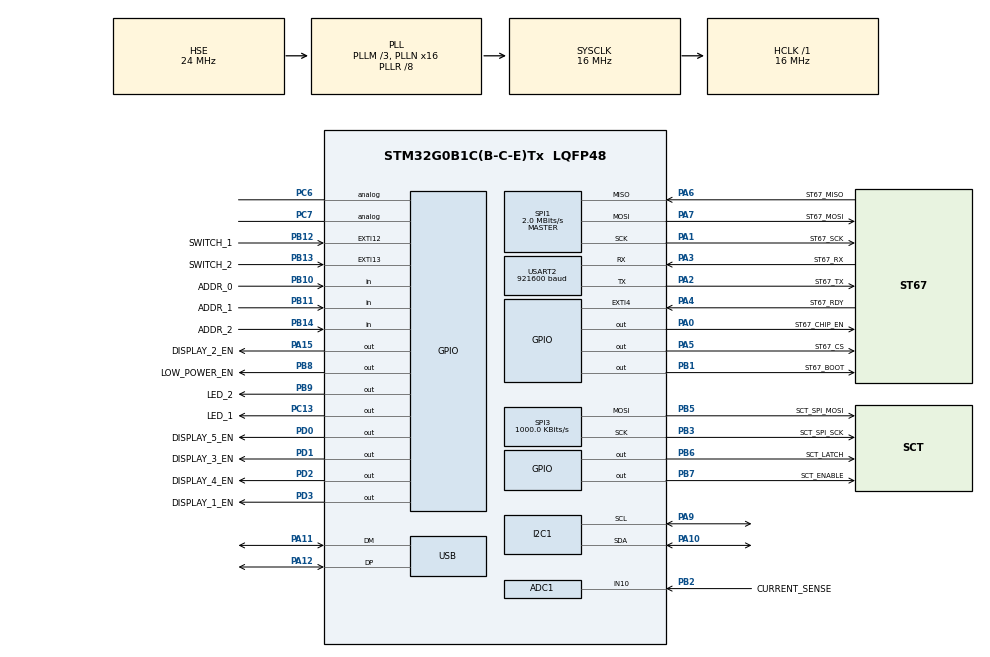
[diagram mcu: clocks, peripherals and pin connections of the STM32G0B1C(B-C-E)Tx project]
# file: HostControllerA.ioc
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ADC1.Channel-0\#ChannelRegularConversion=ADC_CHANNEL_10
ADC1.Channel-1\#ChannelRegularConversion=ADC_CHANNEL_TEMPSENSOR
ADC1.Channel-2\#ChannelRegularConversion=ADC_CHANNEL_VREFINT
ADC1.NbrOfConversion=3
ADC1.NbrOfConversionFlag=1
ADC1.OversamplingMode=ENABLE
ADC1.Rank-0\#ChannelRegularConversion=1
ADC1.Rank-1\#ChannelRegularConversion=2
ADC1.Rank-2\#ChannelRegularConversion=3
ADC1.Ratio=ADC_OVERSAMPLING_RATIO_16
ADC1.RightBitShift=ADC_RIGHTBITSHIFT_4
ADC1.SamplingTime-0\#ChannelRegularConversion=ADC_SAMPLINGTIME_COMMON_1
ADC1.SamplingTime-1\#ChannelRegularConversion=ADC_SAMPLINGTIME_COMMON_1
ADC1.SamplingTime-2\#ChannelRegularConversion=ADC_SAMPLINGTIME_COMMON_1
ADC1.SamplingTimeCommon1=ADC_SAMPLETIME_160CYCLES_5
ADC1.SamplingTimeCommon2=ADC_SAMPLETIME_160CYCLES_5
ADC1.SelectedChannel=ADC_CHANNEL_TEMPSENSOR|ADC_CHANNEL_VREFINT|ADC_CHANNEL_10
ADC1.TriggerFrequencyMode=ADC_TRIGGER_FREQ_LOW
ADC1.master=1
Dma.ADC1.2.Direction=DMA_PERIPH_TO_MEMORY
Dma.ADC1.2.EventEnable=DISABLE
Dma.ADC1.2.Instance=DMA1_Channel3
Dma.ADC1.2.MemDataAlignment=DMA_MDATAALIGN_HALFWORD
Dma.ADC1.2.MemInc=DMA_MINC_ENABLE
Dma.ADC1.2.Mode=DMA_NORMAL
Dma.ADC1.2.PeriphDataAlignment=DMA_PDATAALIGN_HALFWORD
Dma.ADC1.2.PeriphInc=DMA_PINC_DISABLE
Dma.ADC1.2.Polarity=HAL_DMAMUX_REQ_GEN_RISING
Dma.ADC1.2.Priority=DMA_PRIORITY_LOW
Dma.ADC1.2.RequestNumber=1
Dma.ADC1.2.SignalID=NONE
Dma.ADC1.2.SyncEnable=DISABLE
Dma.ADC1.2.SyncPolarity=HAL_DMAMUX_SYNC_NO_EVENT
Dma.ADC1.2.SyncRequestNumber=1
Dma.ADC1.2.SyncSignalID=NONE
Dma.Request0=SPI1_RX
Dma.Request1=SPI1_TX
Dma.Request2=ADC1
Dma.Request3=SPI3_TX
Dma.SPI1_RX.0.Direction=DMA_PERIPH_TO_MEMORY
Dma.SPI1_RX.0.EventEnable=DISABLE
Dma.SPI1_RX.0.Instance=DMA1_Channel1
Dma.SPI1_RX.0.MemDataAlignment=DMA_MDATAALIGN_BYTE
Dma.SPI1_RX.0.MemInc=DMA_MINC_ENABLE
Dma.SPI1_RX.0.Mode=DMA_NORMAL
Dma.SPI1_RX.0.PeriphDataAlignment=DMA_PDATAALIGN_BYTE
Dma.SPI1_RX.0.PeriphInc=DMA_PINC_DISABLE
Dma.SPI1_RX.0.Polarity=HAL_DMAMUX_REQ_GEN_RISING
Dma.SPI1_RX.0.Priority=DMA_PRIORITY_HIGH
Dma.SPI1_RX.0.RequestNumber=1
Dma.SPI1_RX.0.SignalID=NONE
Dma.SPI1_RX.0.SyncEnable=DISABLE
Dma.SPI1_RX.0.SyncPolarity=HAL_DMAMUX_SYNC_NO_EVENT
Dma.SPI1_RX.0.SyncRequestNumber=1
Dma.SPI1_RX.0.SyncSignalID=NONE
Dma.SPI1_TX.1.Direction=DMA_MEMORY_TO_PERIPH
Dma.SPI1_TX.1.EventEnable=DISABLE
Dma.SPI1_TX.1.Instance=DMA1_Channel2
Dma.SPI1_TX.1.MemDataAlignment=DMA_MDATAALIGN_BYTE
Dma.SPI1_TX.1.MemInc=DMA_MINC_ENABLE
Dma.SPI1_TX.1.Mode=DMA_NORMAL
Dma.SPI1_TX.1.PeriphDataAlignment=DMA_PDATAALIGN_BYTE
Dma.SPI1_TX.1.PeriphInc=DMA_PINC_DISABLE
Dma.SPI1_TX.1.Polarity=HAL_DMAMUX_REQ_GEN_RISING
Dma.SPI1_TX.1.Priority=DMA_PRIORITY_HIGH
Dma.SPI1_TX.1.RequestNumber=1
Dma.SPI1_TX.1.SignalID=NONE
Dma.SPI1_TX.1.SyncEnable=DISABLE
Dma.SPI1_TX.1.SyncPolarity=HAL_DMAMUX_SYNC_NO_EVENT
Dma.SPI1_TX.1.SyncRequestNumber=1
Dma.SPI1_TX.1.SyncSignalID=NONE
Dma.SPI3_TX.3.Direction=DMA_MEMORY_TO_PERIPH
Dma.SPI3_TX.3.EventEnable=DISABLE
Dma.SPI3_TX.3.Instance=DMA1_Channel4
Dma.SPI3_TX.3.MemDataAlignment=DMA_MDATAALIGN_BYTE
Dma.SPI3_TX.3.MemInc=DMA_MINC_ENABLE
Dma.SPI3_TX.3.Mode=DMA_NORMAL
Dma.SPI3_TX.3.PeriphDataAlignment=DMA_PDATAALIGN_BYTE
Dma.SPI3_TX.3.PeriphInc=DMA_PINC_DISABLE
Dma.SPI3_TX.3.Polarity=HAL_DMAMUX_REQ_GEN_RISING
Dma.SPI3_TX.3.Priority=DMA_PRIORITY_HIGH
Dma.SPI3_TX.3.RequestNumber=1
Dma.SPI3_TX.3.SignalID=NONE
Dma.SPI3_TX.3.SyncEnable=DISABLE
Dma.SPI3_TX.3.SyncPolarity=HAL_DMAMUX_SYNC_NO_EVENT
Dma.SPI3_TX.3.SyncRequestNumber=1
Dma.SPI3_TX.3.SyncSignalID=NONE
FREERTOS.Tasks01=defaultTask,24,128,StartDefaultTask,Default,NULL,Dynamic,NULL,NULL
FREERTOS.configTOTAL_HEAP_SIZE=32000
FREERTOS.configUSE_NEWLIB_REENTRANT=1
I2C1.OwnAddress=8
I2C1.Speed=100
I2C1.Timing=0x00503D58
Mcu.Family=STM32G0
Mcu.Name=STM32G0B1C(B-C-E)Tx
Mcu.Package=LQFP48
NVIC.ADC1_COMP_IRQn=true\:3\:0\:false\:false\:true\:true\:true\:true\:true
NVIC.DMA1_Ch4_7_DMA2_Ch1_5_DMAMUX1_OVR_IRQn=true\:3\:0\:false\:false\:true\:true\:false\:true\:true
NVIC.DMA1_Channel1_IRQn=true\:3\:0\:false\:false\:true\:true\:false\:true\:true
NVIC.DMA1_Channel2_3_IRQn=true\:3\:0\:false\:false\:true\:true\:false\:true\:true
NVIC.EXTI4_15_IRQn=true\:3\:0\:false\:false\:true\:true\:true\:true\:true
NVIC.TIM1_BRK_UP_TRG_COM_IRQn=true\:3\:0\:false\:false\:true\:false\:false\:true\:true
NVIC.TIM2_IRQn=true\:3\:0\:false\:false\:true\:true\:true\:true\:true
NVIC.TimeBase=TIM1_BRK_UP_TRG_COM_IRQn
NVIC.TimeBaseIP=TIM1
NVIC.USB_UCPD1_2_IRQn=true\:1\:0\:false\:false\:true\:true\:true\:true\:true
PA0.GPIO_Label=ST67_CHIP_EN
PA0.GPIO_Speed=GPIO_SPEED_FREQ_HIGH
PA0.Signal=GPIO_Output
PA1.GPIO_Label=ST67_SCK
PA1.GPIO_Speed=GPIO_SPEED_FREQ_VERY_HIGH
PA1.Mode=Full_Duplex_Master
PA1.Signal=SPI1_SCK
PA10.GPIO_Pu=GPIO_NOPULL
PA10.Mode=I2C
PA10.Signal=I2C1_SDA
PA11\ [PA9].Mode=Device
PA11\ [PA9].Signal=USB_DM
PA12\ [PA10].Mode=Device
PA12\ [PA10].Signal=USB_DP
PA13.Mode=Serial_Wire
PA13.Signal=SYS_SWDIO
PA14-BOOT0.Mode=Serial_Wire
PA14-BOOT0.Signal=SYS_SWCLK
PA15.GPIO_Label=DISPLAY_2_EN
PA15.PinState=GPIO_PIN_SET
PA15.Signal=GPIO_Output
PA2.GPIO_Label=ST67_TX
PA2.Mode=Asynchronous
PA2.Signal=USART2_TX
PA3.GPIO_Label=ST67_RX
PA3.Mode=Asynchronous
PA3.Signal=USART2_RX
PA4.GPIO_Label=ST67_RDY
PA4.GPIO_ModeDefaultEXTI=GPIO_MODE_IT_RISING_FALLING
PA4.GPIO_PuPd=GPIO_PULLDOWN
PA4.Signal=GPXTI4
PA5.GPIO_Label=ST67_CS
PA5.GPIO_Speed=GPIO_SPEED_FREQ_HIGH
PA5.Signal=GPIO_Output
PA6.GPIO_Label=ST67_MISO
PA6.GPIO_Speed=GPIO_SPEED_FREQ_VERY_HIGH
PA6.Mode=Full_Duplex_Master
PA6.Signal=SPI1_MISO
PA7.GPIO_Label=ST67_MOSI
PA7.GPIO_Speed=GPIO_SPEED_FREQ_VERY_HIGH
PA7.Mode=Full_Duplex_Master
PA7.Signal=SPI1_MOSI
PA9.GPIO_Pu=GPIO_NOPULL
PA9.Mode=I2C
PA9.Signal=I2C1_SCL
PB1.GPIO_Label=ST67_BOOT
PB1.Signal=GPIO_Output
PB10.GPIO_Label=ADDR_0
PB10.GPIO_PuPd=GPIO_PULLDOWN
PB10.Signal=GPIO_Input
PB11.GPIO_Label=ADDR_1
PB11.GPIO_PuPd=GPIO_PULLDOWN
PB11.Signal=GPIO_Input
PB12.GPIO_Label=SWITCH_1
PB12.GPIO_ModeDefaultEXTI=GPIO_MODE_IT_FALLING
PB12.GPIO_PuPd=GPIO_PULLUP
PB12.Signal=GPXTI12
PB13.GPIO_Label=SWITCH_2
PB13.GPIO_ModeDefaultEXTI=GPIO_MODE_IT_FALLING
PB13.GPIO_PuPd=GPIO_PULLUP
PB13.Signal=GPXTI13
PB14.GPIO_Label=ADDR_2
PB14.GPIO_PuPd=GPIO_PULLDOWN
PB14.Signal=GPIO_Input
PB2.GPIO_Label=CURRENT_SENSE
PB2.Mode=IN10
PB2.Signal=ADC1_IN10
PB3.GPIO_Label=SCT_SPI_SCK
PB3.Mode=TX_Only_Simplex_Unidirect_Master
PB3.Signal=SPI3_SCK
PB5.GPIO_Label=SCT_SPI_MOSI
PB5.Mode=TX_Only_Simplex_Unidirect_Master
PB5.Signal=SPI3_MOSI
PB6.GPIO_Label=SCT_LATCH
PB6.Signal=GPIO_Output
PB7.GPIO_Label=SCT_ENABLE
PB7.Signal=GPIO_Output
PB8.GPIO_Label=LOW_POWER_EN
PB8.Signal=GPIO_Output
PB9.GPIO_Label=LED_2
PB9.Signal=GPIO_Output
PC13.GPIO_Label=LED_1
PC13.Signal=GPIO_Output
PC6.Signal=GPIO_Analog
PC7.Signal=GPIO_Analog
PD0.GPIO_Label=DISPLAY_5_EN
PD0.PinState=GPIO_PIN_SET
PD0.Signal=GPIO_Output
PD1.GPIO_Label=DISPLAY_3_EN
PD1.PinState=GPIO_PIN_SET
PD1.Signal=GPIO_Output
PD2.GPIO_Label=DISPLAY_4_EN
PD2.PinState=GPIO_PIN_SET
PD2.Signal=GPIO_Output
PD3.GPIO_Label=DISPLAY_1_EN
PD3.PinState=GPIO_PIN_SET
PD3.Signal=GPIO_Output
PF0-OSC_IN\ (PF0).Mode=HSE-External-Oscillator
PF0-OSC_IN\ (PF0).Signal=RCC_OSC_IN
PF1-OSC_OUT\ (PF1).Mode=HSE-External-Oscillator
PF1-OSC_OUT\ (PF1).Signal=RCC_OSC_OUT
ProjectManager.HeapSize=0x200
ProjectManager.StackSize=0x400
ProjectManager.TargetToolchain=CMake
RCC.AHBFreq_Value=16000000
RCC.CortexFreq_Value=16000000
RCC.EXTERNAL_CLOCK_VALUE=48000
RCC.HCLKFreq_Value=16000000
RCC.HSE_VALUE=24000000
RCC.HSI48_VALUE=48000000
RCC.HSI_VALUE=16000000
RCC.LSE_VALUE=32768
RCC.PLLM=RCC_PLLM_DIV3
RCC.PLLN=16
RCC.PLLR=RCC_PLLR_DIV8
RCC.PLLSourceVirtual=RCC_PLLSOURCE_HSE
RCC.RTCClockSelection=RCC_RTCCLKSOURCE_HSE_DIV32
RCC.SYSCLKFreq_VALUE=16000000
RCC.SYSCLKSource=RCC_SYSCLKSOURCE_PLLCLK
RCC.USBFreq_Value=48000000
RCC.VCOOutputFreq_Value=128000000
RTC.AsynchPrediv=124
RTC.Format=RTC_FORMAT_BIN
RTC.Month=RTC_MONTH_SEPTEMBER
RTC.SynchPrediv=5999
SPI1.BaudRatePrescaler=SPI_BAUDRATEPRESCALER_8
SPI1.CalculateBaudRate=2.0 MBits/s
SPI1.DataSize=SPI_DATASIZE_8BIT
SPI1.Direction=SPI_DIRECTION_2LINES
SPI1.Mode=SPI_MODE_MASTER
SPI1.VirtualType=VM_MASTER
SPI3.BaudRatePrescaler=SPI_BAUDRATEPRESCALER_16
SPI3.CalculateBaudRate=1000.0 KBits/s
SPI3.DataSize=SPI_DATASIZE_8BIT
SPI3.Direction=SPI_DIRECTION_2LINES
SPI3.Mode=SPI_MODE_MASTER
SPI3.VirtualType=VM_MASTER
STMicroelectronics.X-CUBE-ST67W61.1.3.0.BSP.number=1
STMicroelectronics.X-CUBE-ST67W61.1.3.0.ST67W6XIiNetworkIiDriverCcNetworkJjATDriver=true
STMicroelectronics.X-CUBE-ST67W61.1.3.0.ST67W6XIiNetworkIiDriverCcNetworkJjST67OoArchitecture=T01
STMicroelectronics.X-CUBE-ST67W61.1.3.0.ST67W6XIiNetworkIiDriverCcNetworkJjServiceAPI=true
STMicroelectronics.X-CUBE-ST67W61.1.3.00.BSP.STBoard=false
STMicroelectronics.X-CUBE-ST67W61.1.3.00.BSP.api=Unknown
STMicroelectronics.X-CUBE-ST67W61.1.3.00.BSP.instance=SPI1
STMicroelectronics.X-CUBE-ST67W61.1.3.00.BSP.ip=SPI
STMicroelectronics.X-CUBE-ST67W61.1.3.00.BSP.mode=Full-Duplex Master
STMicroelectronics.X-CUBE-ST67W61.1.3.00.BSP.name=NCP_SPI
STMicroelectronics.X-CUBE-ST67W61.1.3.00.BSP.solution=SPI1
TIM2.Period=3999
TIM2.Prescaler=15
USART2.BaudRate=921600
USART2.VirtualMode-Asynchronous=VM_ASYNC
USB_DEVICE.CLASS_NAME_FS=CDC
USB_DEVICE.VirtualMode=Cdc
USB_DEVICE.VirtualModeFS=Cdc_FS
VP_ADC1_TempSens_Input.Mode=IN-TempSens
VP_ADC1_Vref_Input.Mode=IN-Vrefint
VP_FREERTOS_VS_CMSIS_V2.Mode=CMSIS_V2
VP_RCC_USB.Mode=CRS SYNC Source USB
VP_RTC_VS_RTC_Activate.Mode=RTC_Enabled
VP_RTC_VS_RTC_Calendar.Mode=RTC_Calendar
VP_STMicroelectronics.X-CUBE-ST67W61_VS_NetworkJjST67W6XIiNetworkIiDriver_1.3.0_1.3.0.Mode=NetworkJjST67W6XIiNetworkIiDriver
VP_SYS_VS_DBSignals.Mode=DisableDeadBatterySignals
VP_SYS_VS_tim1.Mode=TIM1
VP_TIM2_VS_ClockSourceINT.Mode=Internal
VP_USB_DEVICE_VS_USB_DEVICE_CDC_FS.Mode=CDC_FS
board=custom

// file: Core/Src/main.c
/* USER CODE BEGIN Header */
/**
  ******************************************************************************
  * @file           : main.c
  * @brief          : Main program body
  ******************************************************************************
  * @attention
  *
  * Copyright (c) 2026 STMicroelectronics.
  * All rights reserved.
  *
  * This software is licensed under terms that can be found in the LICENSE file
  * in the root directory of this software component.
  * If no LICENSE file comes with this software, it is provided AS-IS.
  *
  ******************************************************************************
  */
/* USER CODE END Header */
#include "main.h"
#include "cmsis_os.h"
#include "usb_device.h"

/* USER CODE BEGIN Includes */
#include <AstroWeather.hpp>
#include "task.h"
#include "stm32g0xx_ll_crs.h"
/* USER CODE END Includes */

ADC_HandleTypeDef hadc1;
DMA_HandleTypeDef hdma_adc1;

I2C_HandleTypeDef hi2c1;

RTC_HandleTypeDef hrtc;

SPI_HandleTypeDef hspi1;
SPI_HandleTypeDef hspi3;
DMA_HandleTypeDef hdma_spi1_rx;
DMA_HandleTypeDef hdma_spi1_tx;
DMA_HandleTypeDef hdma_spi3_tx;

TIM_HandleTypeDef htim2;

UART_HandleTypeDef huart2;

/* Definitions for defaultTask */
osThreadId_t defaultTaskHandle;
const osThreadAttr_t defaultTask_attributes = {
  .name = "defaultTask",
  .priority = (osPriority_t) osPriorityNormal,
  .stack_size = 128 * 4
};

void SystemClock_Config(void);
static void MX_GPIO_Init(void);
static void MX_DMA_Init(void);
static void MX_SPI1_Init(void);
static void MX_USART2_UART_Init(void);
static void MX_SPI3_Init(void);
static void MX_I2C1_Init(void);
static void MX_TIM2_Init(void);
static void MX_ADC1_Init(void);
static void MX_RTC_Init(void);
void StartDefaultTask(void *argument);

int main(void)
{

  /* MCU Configuration--------------------------------------------------------*/

  /* Reset of all peripherals, Initializes the Flash interface and the Systick. */
  HAL_Init();

  /* Configure the system clock */
  SystemClock_Config();

  /* USER CODE BEGIN SysInit */
  /* CubeMX generates HSI48CalibrationValue = 32 whatever the GUI shows: the
     midpoint of the 6-bit TRIM on other families. The G0's TRIM is 7 bits
     with its midpoint and reset value at 64, so start the CRS there. USB is
     not running yet, so the CRS has not trimmed anything. */
  LL_CRS_DisableAutoTrimming();
  LL_CRS_SetHSI48SmoothTrimming(LL_CRS_HSI48CALIBRATION_DEFAULT);
  LL_CRS_EnableAutoTrimming();
  /* USER CODE END SysInit */

  /* Initialize all configured peripherals */
  MX_GPIO_Init();
  MX_DMA_Init();
  MX_SPI1_Init();
  MX_USART2_UART_Init();
  MX_SPI3_Init();
  MX_I2C1_Init();
  MX_TIM2_Init();
  MX_ADC1_Init();
  MX_RTC_Init();

  /* Init scheduler */
  osKernelInitialize();

  /* Create the thread(s) */
  /* creation of defaultTask */
  defaultTaskHandle = osThreadNew(StartDefaultTask, NULL, &defaultTask_attributes);

  /* USER CODE BEGIN RTOS_THREADS */
  AstroWeather_Init();
  /* USER CODE END RTOS_THREADS */

  /* Start scheduler */
  osKernelStart();

  /* We should never get here as control is now taken by the scheduler */

  /* Infinite loop */
  while (1)
  {

  }
}

void SystemClock_Config(void)
{
  RCC_OscInitTypeDef RCC_OscInitStruct = {0};
  RCC_ClkInitTypeDef RCC_ClkInitStruct = {0};
  RCC_CRSInitTypeDef pInit = {0};

  /** Configure the main internal regulator output voltage
  */
  HAL_PWREx_ControlVoltageScaling(PWR_REGULATOR_VOLTAGE_SCALE1);

  /** Initializes the RCC Oscillators according to the specified parameters
  * in the RCC_OscInitTypeDef structure.
  */
  RCC_OscInitStruct.OscillatorType = RCC_OSCILLATORTYPE_HSE|RCC_OSCILLATORTYPE_HSI48;
  RCC_OscInitStruct.HSEState = RCC_HSE_ON;
  RCC_OscInitStruct.HSI48State = RCC_HSI48_ON;
  RCC_OscInitStruct.PLL.PLLState = RCC_PLL_ON;
  RCC_OscInitStruct.PLL.PLLSource = RCC_PLLSOURCE_HSE;
  RCC_OscInitStruct.PLL.PLLM = RCC_PLLM_DIV3;
  RCC_OscInitStruct.PLL.PLLN = 16;
  RCC_OscInitStruct.PLL.PLLP = RCC_PLLP_DIV2;
  RCC_OscInitStruct.PLL.PLLQ = RCC_PLLQ_DIV2;
  RCC_OscInitStruct.PLL.PLLR = RCC_PLLR_DIV8;
  if (HAL_RCC_OscConfig(&RCC_OscInitStruct) != HAL_OK)
  {
    Error_Handler();
  }

  /** Initializes the CPU, AHB and APB buses clocks
  */
  RCC_ClkInitStruct.ClockType = RCC_CLOCKTYPE_HCLK|RCC_CLOCKTYPE_SYSCLK
                              |RCC_CLOCKTYPE_PCLK1;
  RCC_ClkInitStruct.SYSCLKSource = RCC_SYSCLKSOURCE_PLLCLK;
  RCC_ClkInitStruct.AHBCLKDivider = RCC_SYSCLK_DIV1;
  RCC_ClkInitStruct.APB1CLKDivider = RCC_HCLK_DIV1;

  if (HAL_RCC_ClockConfig(&RCC_ClkInitStruct, FLASH_LATENCY_0) != HAL_OK)
  {
    Error_Handler();
  }

  /** Enable the SYSCFG APB clock
  */
  __HAL_RCC_CRS_CLK_ENABLE();

  /** Configures CRS
  */
  pInit.Prescaler = RCC_CRS_SYNC_DIV1;
  pInit.Source = RCC_CRS_SYNC_SOURCE_USB;
  pInit.Polarity = RCC_CRS_SYNC_POLARITY_RISING;
  pInit.ReloadValue = __HAL_RCC_CRS_RELOADVALUE_CALCULATE(48000000,1000);
  pInit.ErrorLimitValue = 34;
  pInit.HSI48CalibrationValue = 32;

  HAL_RCCEx_CRSConfig(&pInit);
}

static void MX_ADC1_Init(void)
{

  ADC_ChannelConfTypeDef sConfig = {0};

  /** Configure the global features of the ADC (Clock, Resolution, Data Alignment and number of conversion)
  */
  hadc1.Instance = ADC1;
  hadc1.Init.ClockPrescaler = ADC_CLOCK_SYNC_PCLK_DIV2;
  hadc1.Init.Resolution = ADC_RESOLUTION_12B;
  hadc1.Init.DataAlign = ADC_DATAALIGN_RIGHT;
  hadc1.Init.ScanConvMode = ADC_SCAN_ENABLE;
  hadc1.Init.EOCSelection = ADC_EOC_SINGLE_CONV;
  hadc1.Init.LowPowerAutoWait = DISABLE;
  hadc1.Init.LowPowerAutoPowerOff = DISABLE;
  hadc1.Init.ContinuousConvMode = DISABLE;
  hadc1.Init.NbrOfConversion = 3;
  hadc1.Init.DiscontinuousConvMode = DISABLE;
  hadc1.Init.ExternalTrigConv = ADC_SOFTWARE_START;
  hadc1.Init.ExternalTrigConvEdge = ADC_EXTERNALTRIGCONVEDGE_NONE;
  hadc1.Init.DMAContinuousRequests = DISABLE;
  hadc1.Init.Overrun = ADC_OVR_DATA_PRESERVED;
  hadc1.Init.SamplingTimeCommon1 = ADC_SAMPLETIME_160CYCLES_5;
  hadc1.Init.SamplingTimeCommon2 = ADC_SAMPLETIME_160CYCLES_5;
  hadc1.Init.OversamplingMode = ENABLE;
  hadc1.Init.Oversampling.Ratio = ADC_OVERSAMPLING_RATIO_16;
  hadc1.Init.Oversampling.RightBitShift = ADC_RIGHTBITSHIFT_4;
  hadc1.Init.Oversampling.TriggeredMode = ADC_TRIGGEREDMODE_SINGLE_TRIGGER;
  hadc1.Init.TriggerFrequencyMode = ADC_TRIGGER_FREQ_LOW;
  if (HAL_ADC_Init(&hadc1) != HAL_OK)
  {
    Error_Handler();
  }

  /** Configure Regular Channel
  */
  sConfig.Channel = ADC_CHANNEL_10;
  sConfig.Rank = ADC_REGULAR_RANK_1;
  sConfig.SamplingTime = ADC_SAMPLINGTIME_COMMON_1;
  if (HAL_ADC_ConfigChannel(&hadc1, &sConfig) != HAL_OK)
  {
    Error_Handler();
  }

  /** Configure Regular Channel
  */
  sConfig.Channel = ADC_CHANNEL_TEMPSENSOR;
  sConfig.Rank = ADC_REGULAR_RANK_2;
  if (HAL_ADC_ConfigChannel(&hadc1, &sConfig) != HAL_OK)
  {
    Error_Handler();
  }

  /** Configure Regular Channel
  */
  sConfig.Channel = ADC_CHANNEL_VREFINT;
  sConfig.Rank = ADC_REGULAR_RANK_3;
  if (HAL_ADC_ConfigChannel(&hadc1, &sConfig) != HAL_OK)
  {
    Error_Handler();
  }

}

static void MX_I2C1_Init(void)
{

  hi2c1.Instance = I2C1;
  hi2c1.Init.Timing = 0x00503D58;
  hi2c1.Init.OwnAddress1 = 16;
  hi2c1.Init.AddressingMode = I2C_ADDRESSINGMODE_7BIT;
  hi2c1.Init.DualAddressMode = I2C_DUALADDRESS_DISABLE;
  hi2c1.Init.OwnAddress2 = 0;
  hi2c1.Init.OwnAddress2Masks = I2C_OA2_NOMASK;
  hi2c1.Init.GeneralCallMode = I2C_GENERALCALL_DISABLE;
  hi2c1.Init.NoStretchMode = I2C_NOSTRETCH_DISABLE;
  if (HAL_I2C_Init(&hi2c1) != HAL_OK)
  {
    Error_Handler();
  }

  /** Configure Analogue filter
  */
  if (HAL_I2CEx_ConfigAnalogFilter(&hi2c1, I2C_ANALOGFILTER_ENABLE) != HAL_OK)
  {
    Error_Handler();
  }

  /** Configure Digital filter
  */
  if (HAL_I2CEx_ConfigDigitalFilter(&hi2c1, 0) != HAL_OK)
  {
    Error_Handler();
  }

}

static void MX_RTC_Init(void)
{

  RTC_TimeTypeDef sTime = {0};
  RTC_DateTypeDef sDate = {0};

  /** Initialize RTC Only
  */
  hrtc.Instance = RTC;
  hrtc.Init.HourFormat = RTC_HOURFORMAT_24;
  hrtc.Init.AsynchPrediv = 124;
  hrtc.Init.SynchPrediv = 5999;
  hrtc.Init.OutPut = RTC_OUTPUT_DISABLE;
  hrtc.Init.OutPutRemap = RTC_OUTPUT_REMAP_NONE;
  hrtc.Init.OutPutPolarity = RTC_OUTPUT_POLARITY_HIGH;
  hrtc.Init.OutPutType = RTC_OUTPUT_TYPE_OPENDRAIN;
  hrtc.Init.OutPutPullUp = RTC_OUTPUT_PULLUP_NONE;
  if (HAL_RTC_Init(&hrtc) != HAL_OK)
  {
    Error_Handler();
  }

  /* USER CODE BEGIN Check_RTC_BKUP */
  /* Time set before a reset: keep it. HAL_RTC_Init() above left the calendar
   * and prescalers alone, as setting the time also sets a non-zero year. */
  if (HAL_RTCEx_BKUPRead(&hrtc, RTC_TIME_SET_BKP_REGISTER) == RTC_TIME_SET_MARKER)
  {
    return;
  }

  /* USER CODE END Check_RTC_BKUP */

  /** Initialize RTC and set the Time and Date
  */
  sTime.Hours = 0;
  sTime.Minutes = 0;
  sTime.Seconds = 0;
  sTime.SubSeconds = 0;
  sTime.DayLightSaving = RTC_DAYLIGHTSAVING_NONE;
  sTime.StoreOperation = RTC_STOREOPERATION_RESET;
  if (HAL_RTC_SetTime(&hrtc, &sTime, RTC_FORMAT_BIN) != HAL_OK)
  {
    Error_Handler();
  }
  sDate.WeekDay = RTC_WEEKDAY_MONDAY;
  sDate.Month = RTC_MONTH_SEPTEMBER;
  sDate.Date = 1;
  sDate.Year = 0;

  if (HAL_RTC_SetDate(&hrtc, &sDate, RTC_FORMAT_BIN) != HAL_OK)
  {
    Error_Handler();
  }

}

static void MX_SPI1_Init(void)
{

  /* SPI1 parameter configuration*/
  hspi1.Instance = SPI1;
  hspi1.Init.Mode = SPI_MODE_MASTER;
  hspi1.Init.Direction = SPI_DIRECTION_2LINES;
  hspi1.Init.DataSize = SPI_DATASIZE_8BIT;
  hspi1.Init.CLKPolarity = SPI_POLARITY_LOW;
  hspi1.Init.CLKPhase = SPI_PHASE_1EDGE;
  hspi1.Init.NSS = SPI_NSS_SOFT;
  hspi1.Init.BaudRatePrescaler = SPI_BAUDRATEPRESCALER_8;
  hspi1.Init.FirstBit = SPI_FIRSTBIT_MSB;
  hspi1.Init.TIMode = SPI_TIMODE_DISABLE;
  hspi1.Init.CRCCalculation = SPI_CRCCALCULATION_DISABLE;
  hspi1.Init.CRCPolynomial = 7;
  hspi1.Init.CRCLength = SPI_CRC_LENGTH_DATASIZE;
  hspi1.Init.NSSPMode = SPI_NSS_PULSE_ENABLE;
  if (HAL_SPI_Init(&hspi1) != HAL_OK)
  {
    Error_Handler();
  }

}

static void MX_SPI3_Init(void)
{

  /* SPI3 parameter configuration*/
  hspi3.Instance = SPI3;
  hspi3.Init.Mode = SPI_MODE_MASTER;
  hspi3.Init.Direction = SPI_DIRECTION_2LINES;
  hspi3.Init.DataSize = SPI_DATASIZE_8BIT;
  hspi3.Init.CLKPolarity = SPI_POLARITY_LOW;
  hspi3.Init.CLKPhase = SPI_PHASE_1EDGE;
  hspi3.Init.NSS = SPI_NSS_SOFT;
  hspi3.Init.BaudRatePrescaler = SPI_BAUDRATEPRESCALER_16;
  hspi3.Init.FirstBit = SPI_FIRSTBIT_MSB;
  hspi3.Init.TIMode = SPI_TIMODE_DISABLE;
  hspi3.Init.CRCCalculation = SPI_CRCCALCULATION_DISABLE;
  hspi3.Init.CRCPolynomial = 7;
  hspi3.Init.CRCLength = SPI_CRC_LENGTH_DATASIZE;
  hspi3.Init.NSSPMode = SPI_NSS_PULSE_ENABLE;
  if (HAL_SPI_Init(&hspi3) != HAL_OK)
  {
    Error_Handler();
  }

}

static void MX_TIM2_Init(void)
{

  TIM_ClockConfigTypeDef sClockSourceConfig = {0};
  TIM_MasterConfigTypeDef sMasterConfig = {0};

  htim2.Instance = TIM2;
  htim2.Init.Prescaler = 15;
  htim2.Init.CounterMode = TIM_COUNTERMODE_UP;
  htim2.Init.Period = 3999;
  htim2.Init.ClockDivision = TIM_CLOCKDIVISION_DIV1;
  htim2.Init.AutoReloadPreload = TIM_AUTORELOAD_PRELOAD_DISABLE;
  if (HAL_TIM_Base_Init(&htim2) != HAL_OK)
  {
    Error_Handler();
  }
  sClockSourceConfig.ClockSource = TIM_CLOCKSOURCE_INTERNAL;
  if (HAL_TIM_ConfigClockSource(&htim2, &sClockSourceConfig) != HAL_OK)
  {
    Error_Handler();
  }
  sMasterConfig.MasterOutputTrigger = TIM_TRGO_RESET;
  sMasterConfig.MasterSlaveMode = TIM_MASTERSLAVEMODE_DISABLE;
  if (HAL_TIMEx_MasterConfigSynchronization(&htim2, &sMasterConfig) != HAL_OK)
  {
    Error_Handler();
  }

}

static void MX_USART2_UART_Init(void)
{

  huart2.Instance = USART2;
  huart2.Init.BaudRate = 921600;
  huart2.Init.WordLength = UART_WORDLENGTH_8B;
  huart2.Init.StopBits = UART_STOPBITS_1;
  huart2.Init.Parity = UART_PARITY_NONE;
  huart2.Init.Mode = UART_MODE_TX_RX;
  huart2.Init.HwFlowCtl = UART_HWCONTROL_NONE;
  huart2.Init.OverSampling = UART_OVERSAMPLING_16;
  huart2.Init.OneBitSampling = UART_ONE_BIT_SAMPLE_DISABLE;
  huart2.Init.ClockPrescaler = UART_PRESCALER_DIV1;
  huart2.AdvancedInit.AdvFeatureInit = UART_ADVFEATURE_NO_INIT;
  if (HAL_UART_Init(&huart2) != HAL_OK)
  {
    Error_Handler();
  }
  if (HAL_UARTEx_SetTxFifoThreshold(&huart2, UART_TXFIFO_THRESHOLD_1_8) != HAL_OK)
  {
    Error_Handler();
  }
  if (HAL_UARTEx_SetRxFifoThreshold(&huart2, UART_RXFIFO_THRESHOLD_1_8) != HAL_OK)
  {
    Error_Handler();
  }
  if (HAL_UARTEx_DisableFifoMode(&huart2) != HAL_OK)
  {
    Error_Handler();
  }

}

static void MX_DMA_Init(void)
{

  /* DMA controller clock enable */
  __HAL_RCC_DMA1_CLK_ENABLE();

  /* DMA interrupt init */
  /* DMA1_Channel1_IRQn interrupt configuration */
  HAL_NVIC_SetPriority(DMA1_Channel1_IRQn, 3, 0);
  HAL_NVIC_EnableIRQ(DMA1_Channel1_IRQn);
  /* DMA1_Channel2_3_IRQn interrupt configuration */
  HAL_NVIC_SetPriority(DMA1_Channel2_3_IRQn, 3, 0);
  HAL_NVIC_EnableIRQ(DMA1_Channel2_3_IRQn);
  /* DMA1_Ch4_7_DMA2_Ch1_5_DMAMUX1_OVR_IRQn interrupt configuration */
  HAL_NVIC_SetPriority(DMA1_Ch4_7_DMA2_Ch1_5_DMAMUX1_OVR_IRQn, 3, 0);
  HAL_NVIC_EnableIRQ(DMA1_Ch4_7_DMA2_Ch1_5_DMAMUX1_OVR_IRQn);

}

static void MX_GPIO_Init(void)
{
  GPIO_InitTypeDef GPIO_InitStruct = {0};

  /* GPIO Ports Clock Enable */
  __HAL_RCC_GPIOC_CLK_ENABLE();
  __HAL_RCC_GPIOF_CLK_ENABLE();
  __HAL_RCC_GPIOA_CLK_ENABLE();
  __HAL_RCC_GPIOB_CLK_ENABLE();
  __HAL_RCC_GPIOD_CLK_ENABLE();

  /*Configure GPIO pin Output Level */
  HAL_GPIO_WritePin(LED_1_GPIO_Port, LED_1_Pin, GPIO_PIN_RESET);

  /*Configure GPIO pin Output Level */
  HAL_GPIO_WritePin(GPIOA, ST67_CHIP_EN_Pin|ST67_CS_Pin, GPIO_PIN_RESET);

  /*Configure GPIO pin Output Level */
  HAL_GPIO_WritePin(GPIOB, ST67_BOOT_Pin|SCT_LATCH_Pin|SCT_ENABLE_Pin|LOW_POWER_EN_Pin
                          |LED_2_Pin, GPIO_PIN_RESET);

  /*Configure GPIO pin Output Level */
  HAL_GPIO_WritePin(DISPLAY_2_EN_GPIO_Port, DISPLAY_2_EN_Pin, GPIO_PIN_SET);

  /*Configure GPIO pin Output Level */
  HAL_GPIO_WritePin(GPIOD, DISPLAY_5_EN_Pin|DISPLAY_3_EN_Pin|DISPLAY_4_EN_Pin|DISPLAY_1_EN_Pin, GPIO_PIN_SET);

  /*Configure GPIO pin : LED_1_Pin */
  GPIO_InitStruct.Pin = LED_1_Pin;
  GPIO_InitStruct.Mode = GPIO_MODE_OUTPUT_PP;
  GPIO_InitStruct.Pull = GPIO_NOPULL;
  GPIO_InitStruct.Speed = GPIO_SPEED_FREQ_LOW;
  HAL_GPIO_Init(LED_1_GPIO_Port, &GPIO_InitStruct);

  /*Configure GPIO pins : ST67_CHIP_EN_Pin ST67_CS_Pin */
  GPIO_InitStruct.Pin = ST67_CHIP_EN_Pin|ST67_CS_Pin;
  GPIO_InitStruct.Mode = GPIO_MODE_OUTPUT_PP;
  GPIO_InitStruct.Pull = GPIO_NOPULL;
  GPIO_InitStruct.Speed = GPIO_SPEED_FREQ_HIGH;
  HAL_GPIO_Init(GPIOA, &GPIO_InitStruct);

  /*Configure GPIO pin : ST67_RDY_Pin */
  GPIO_InitStruct.Pin = ST67_RDY_Pin;
  GPIO_InitStruct.Mode = GPIO_MODE_IT_RISING_FALLING;
  GPIO_InitStruct.Pull = GPIO_PULLDOWN;
  HAL_GPIO_Init(ST67_RDY_GPIO_Port, &GPIO_InitStruct);

  /*Configure GPIO pins : ST67_BOOT_Pin SCT_LATCH_Pin SCT_ENABLE_Pin LOW_POWER_EN_Pin
                           LED_2_Pin */
  GPIO_InitStruct.Pin = ST67_BOOT_Pin|SCT_LATCH_Pin|SCT_ENABLE_Pin|LOW_POWER_EN_Pin
                          |LED_2_Pin;
  GPIO_InitStruct.Mode = GPIO_MODE_OUTPUT_PP;
  GPIO_InitStruct.Pull = GPIO_NOPULL;
  GPIO_InitStruct.Speed = GPIO_SPEED_FREQ_LOW;
  HAL_GPIO_Init(GPIOB, &GPIO_InitStruct);

  /*Configure GPIO pins : ADDR_0_Pin ADDR_1_Pin ADDR_2_Pin */
  GPIO_InitStruct.Pin = ADDR_0_Pin|ADDR_1_Pin|ADDR_2_Pin;
  GPIO_InitStruct.Mode = GPIO_MODE_INPUT;
  GPIO_InitStruct.Pull = GPIO_PULLDOWN;
  HAL_GPIO_Init(GPIOB, &GPIO_InitStruct);

  /*Configure GPIO pins : SWITCH_1_Pin SWITCH_2_Pin */
  GPIO_InitStruct.Pin = SWITCH_1_Pin|SWITCH_2_Pin;
  GPIO_InitStruct.Mode = GPIO_MODE_IT_FALLING;
  GPIO_InitStruct.Pull = GPIO_PULLUP;
  HAL_GPIO_Init(GPIOB, &GPIO_InitStruct);

  /*Configure GPIO pins : PC6 PC7 */
  GPIO_InitStruct.Pin = GPIO_PIN_6|GPIO_PIN_7;
  GPIO_InitStruct.Mode = GPIO_MODE_ANALOG;
  GPIO_InitStruct.Pull = GPIO_NOPULL;
  HAL_GPIO_Init(GPIOC, &GPIO_InitStruct);

  /*Configure GPIO pin : DISPLAY_2_EN_Pin */
  GPIO_InitStruct.Pin = DISPLAY_2_EN_Pin;
  GPIO_InitStruct.Mode = GPIO_MODE_OUTPUT_PP;
  GPIO_InitStruct.Pull = GPIO_NOPULL;
  GPIO_InitStruct.Speed = GPIO_SPEED_FREQ_LOW;
  HAL_GPIO_Init(DISPLAY_2_EN_GPIO_Port, &GPIO_InitStruct);

  /*Configure GPIO pins : DISPLAY_5_EN_Pin DISPLAY_3_EN_Pin DISPLAY_4_EN_Pin DISPLAY_1_EN_Pin */
  GPIO_InitStruct.Pin = DISPLAY_5_EN_Pin|DISPLAY_3_EN_Pin|DISPLAY_4_EN_Pin|DISPLAY_1_EN_Pin;
  GPIO_InitStruct.Mode = GPIO_MODE_OUTPUT_PP;
  GPIO_InitStruct.Pull = GPIO_NOPULL;
  GPIO_InitStruct.Speed = GPIO_SPEED_FREQ_LOW;
  HAL_GPIO_Init(GPIOD, &GPIO_InitStruct);

  /* EXTI interrupt init*/
  HAL_NVIC_SetPriority(EXTI4_15_IRQn, 3, 0);
  HAL_NVIC_EnableIRQ(EXTI4_15_IRQn);

}

/* USER CODE BEGIN 4 */

volatile const char* g_stackOverflowTaskName = 0;

void vApplicationStackOverflowHook(TaskHandle_t xTask, signed char *pcTaskName)
{
  (void)xTask;
  g_stackOverflowTaskName = (const char*)pcTaskName;
  __disable_irq();
  while (1)
  {
  }
}

/* USER CODE END 4 */

void StartDefaultTask(void *argument)
{
  /* init code for USB_Device */
  MX_USB_Device_Init();
  /* USER CODE BEGIN 5 */
  /* CubeMX will not drop this task, so it ends itself once USB is started:
     USB runs from its interrupt, and the idle task frees this stack. It never
     runs again. */
  osThreadExit();
  /* USER CODE END 5 */
}

void HAL_TIM_PeriodElapsedCallback(TIM_HandleTypeDef *htim)
{
  if (htim->Instance == TIM1)
  {
    HAL_IncTick();
  }
  /* USER CODE BEGIN Callback 1 */
  Display_PcbTimerElapsed(htim);

  /* USER CODE END Callback 1 */
}

void Error_Handler(void)
{
  __disable_irq();
  while (1)
  {
  }
}
